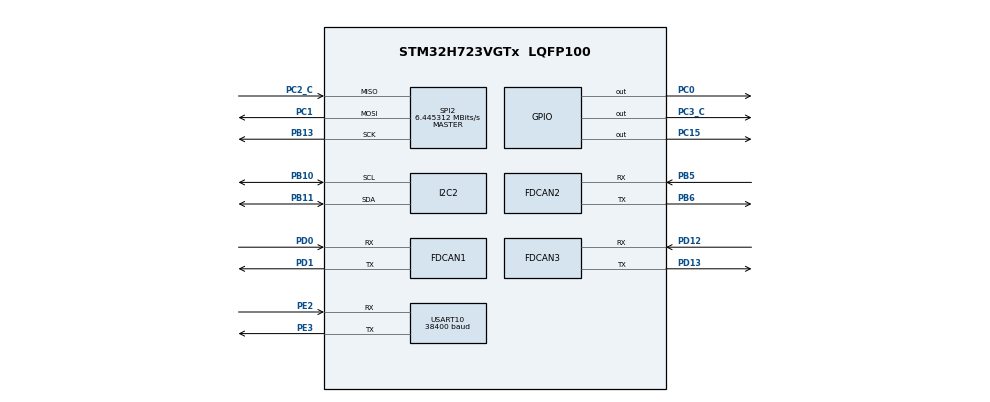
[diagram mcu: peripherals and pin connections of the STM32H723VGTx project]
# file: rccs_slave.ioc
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CORTEX_M7.AccessPermission_S-Cortex_Memory_Protection_Unit_Region1_Settings_S=MPU_REGION_FULL_ACCESS
CORTEX_M7.BaseAddress_S-Cortex_Memory_Protection_Unit_Region1_Settings_S=0x30000000
CORTEX_M7.DisableExec_S-Cortex_Memory_Protection_Unit_Region1_Settings_S=MPU_INSTRUCTION_ACCESS_DISABLE
CORTEX_M7.Enable_S-Cortex_Memory_Protection_Unit_Region1_Settings_S=MPU_REGION_ENABLE
CORTEX_M7.IsShareable_S-Cortex_Memory_Protection_Unit_Region1_Settings_S=MPU_ACCESS_SHAREABLE
CORTEX_M7.Size_S-Cortex_Memory_Protection_Unit_Region1_Settings_S=MPU_REGION_SIZE_32KB
CORTEX_M7.default_mode_Activation=1
Dma.I2C2_RX.2.Direction=DMA_PERIPH_TO_MEMORY
Dma.I2C2_RX.2.EventEnable=DISABLE
Dma.I2C2_RX.2.FIFOMode=DMA_FIFOMODE_DISABLE
Dma.I2C2_RX.2.Instance=DMA1_Stream2
Dma.I2C2_RX.2.MemDataAlignment=DMA_MDATAALIGN_BYTE
Dma.I2C2_RX.2.MemInc=DMA_MINC_ENABLE
Dma.I2C2_RX.2.Mode=DMA_NORMAL
Dma.I2C2_RX.2.PeriphDataAlignment=DMA_PDATAALIGN_BYTE
Dma.I2C2_RX.2.PeriphInc=DMA_PINC_DISABLE
Dma.I2C2_RX.2.Polarity=HAL_DMAMUX_REQ_GEN_RISING
Dma.I2C2_RX.2.Priority=DMA_PRIORITY_MEDIUM
Dma.I2C2_RX.2.RequestNumber=1
Dma.I2C2_RX.2.SignalID=NONE
Dma.I2C2_RX.2.SyncEnable=DISABLE
Dma.I2C2_RX.2.SyncPolarity=HAL_DMAMUX_SYNC_NO_EVENT
Dma.I2C2_RX.2.SyncRequestNumber=1
Dma.I2C2_RX.2.SyncSignalID=NONE
Dma.I2C2_TX.3.Direction=DMA_MEMORY_TO_PERIPH
Dma.I2C2_TX.3.EventEnable=DISABLE
Dma.I2C2_TX.3.FIFOMode=DMA_FIFOMODE_DISABLE
Dma.I2C2_TX.3.Instance=DMA1_Stream3
Dma.I2C2_TX.3.MemDataAlignment=DMA_MDATAALIGN_BYTE
Dma.I2C2_TX.3.MemInc=DMA_MINC_ENABLE
Dma.I2C2_TX.3.Mode=DMA_NORMAL
Dma.I2C2_TX.3.PeriphDataAlignment=DMA_PDATAALIGN_BYTE
Dma.I2C2_TX.3.PeriphInc=DMA_PINC_DISABLE
Dma.I2C2_TX.3.Polarity=HAL_DMAMUX_REQ_GEN_RISING
Dma.I2C2_TX.3.Priority=DMA_PRIORITY_MEDIUM
Dma.I2C2_TX.3.RequestNumber=1
Dma.I2C2_TX.3.SignalID=NONE
Dma.I2C2_TX.3.SyncEnable=DISABLE
Dma.I2C2_TX.3.SyncPolarity=HAL_DMAMUX_SYNC_NO_EVENT
Dma.I2C2_TX.3.SyncRequestNumber=1
Dma.I2C2_TX.3.SyncSignalID=NONE
Dma.Request0=SPI2_RX
Dma.Request1=SPI2_TX
Dma.Request2=I2C2_RX
Dma.Request3=I2C2_TX
Dma.Request4=USART10_RX
Dma.SPI2_RX.0.Direction=DMA_PERIPH_TO_MEMORY
Dma.SPI2_RX.0.EventEnable=DISABLE
Dma.SPI2_RX.0.FIFOMode=DMA_FIFOMODE_DISABLE
Dma.SPI2_RX.0.Instance=DMA1_Stream0
Dma.SPI2_RX.0.MemDataAlignment=DMA_MDATAALIGN_BYTE
Dma.SPI2_RX.0.MemInc=DMA_MINC_ENABLE
Dma.SPI2_RX.0.Mode=DMA_NORMAL
Dma.SPI2_RX.0.PeriphDataAlignment=DMA_PDATAALIGN_BYTE
Dma.SPI2_RX.0.PeriphInc=DMA_PINC_DISABLE
Dma.SPI2_RX.0.Polarity=HAL_DMAMUX_REQ_GEN_RISING
Dma.SPI2_RX.0.Priority=DMA_PRIORITY_LOW
Dma.SPI2_RX.0.RequestNumber=1
Dma.SPI2_RX.0.SignalID=NONE
Dma.SPI2_RX.0.SyncEnable=DISABLE
Dma.SPI2_RX.0.SyncPolarity=HAL_DMAMUX_SYNC_NO_EVENT
Dma.SPI2_RX.0.SyncRequestNumber=1
Dma.SPI2_RX.0.SyncSignalID=NONE
Dma.SPI2_TX.1.Direction=DMA_MEMORY_TO_PERIPH
Dma.SPI2_TX.1.EventEnable=DISABLE
Dma.SPI2_TX.1.FIFOMode=DMA_FIFOMODE_DISABLE
Dma.SPI2_TX.1.Instance=DMA1_Stream1
Dma.SPI2_TX.1.MemDataAlignment=DMA_MDATAALIGN_BYTE
Dma.SPI2_TX.1.MemInc=DMA_MINC_ENABLE
Dma.SPI2_TX.1.Mode=DMA_NORMAL
Dma.SPI2_TX.1.PeriphDataAlignment=DMA_PDATAALIGN_BYTE
Dma.SPI2_TX.1.PeriphInc=DMA_PINC_DISABLE
Dma.SPI2_TX.1.Polarity=HAL_DMAMUX_REQ_GEN_RISING
Dma.SPI2_TX.1.Priority=DMA_PRIORITY_LOW
Dma.SPI2_TX.1.RequestNumber=1
Dma.SPI2_TX.1.SignalID=NONE
Dma.SPI2_TX.1.SyncEnable=DISABLE
Dma.SPI2_TX.1.SyncPolarity=HAL_DMAMUX_SYNC_NO_EVENT
Dma.SPI2_TX.1.SyncRequestNumber=1
Dma.SPI2_TX.1.SyncSignalID=NONE
Dma.USART10_RX.4.Direction=DMA_PERIPH_TO_MEMORY
Dma.USART10_RX.4.EventEnable=DISABLE
Dma.USART10_RX.4.FIFOMode=DMA_FIFOMODE_DISABLE
Dma.USART10_RX.4.Instance=DMA1_Stream6
Dma.USART10_RX.4.MemDataAlignment=DMA_MDATAALIGN_BYTE
Dma.USART10_RX.4.MemInc=DMA_MINC_ENABLE
Dma.USART10_RX.4.Mode=DMA_CIRCULAR
Dma.USART10_RX.4.PeriphDataAlignment=DMA_PDATAALIGN_BYTE
Dma.USART10_RX.4.PeriphInc=DMA_PINC_DISABLE
Dma.USART10_RX.4.Polarity=HAL_DMAMUX_REQ_GEN_RISING
Dma.USART10_RX.4.Priority=DMA_PRIORITY_LOW
Dma.USART10_RX.4.RequestNumber=1
Dma.USART10_RX.4.SignalID=NONE
Dma.USART10_RX.4.SyncEnable=DISABLE
Dma.USART10_RX.4.SyncPolarity=HAL_DMAMUX_SYNC_NO_EVENT
Dma.USART10_RX.4.SyncRequestNumber=1
Dma.USART10_RX.4.SyncSignalID=NONE
FDCAN1.CalculateBaudRateNominal=1000000
FDCAN1.CalculateTimeBitNominal=1000
FDCAN1.CalculateTimeQuantumNominal=41.666666666666664
FDCAN1.NominalPrescaler=1
FDCAN1.NominalSyncJumpWidth=3
FDCAN1.NominalTimeSeg1=20
FDCAN1.NominalTimeSeg2=3
FDCAN1.RxFifo0ElmtsNbr=32
FDCAN1.StdFiltersNbr=8
FDCAN1.TxFifoQueueElmtsNbr=32
FDCAN2.CalculateBaudRateNominal=1000000
FDCAN2.CalculateTimeBitNominal=1000
FDCAN2.CalculateTimeQuantumNominal=41.666666666666664
FDCAN2.MessageRAMOffset=264
FDCAN2.NominalPrescaler=1
FDCAN2.NominalSyncJumpWidth=3
FDCAN2.NominalTimeSeg1=20
FDCAN2.NominalTimeSeg2=3
FDCAN2.RxFifo0ElmtsNbr=32
FDCAN2.TxFifoQueueElmtsNbr=32
FDCAN3.CalculateBaudRateNominal=1000000
FDCAN3.CalculateTimeBitNominal=1000
FDCAN3.CalculateTimeQuantumNominal=41.666666666666664
FDCAN3.MessageRAMOffset=528
FDCAN3.NominalPrescaler=1
FDCAN3.NominalSyncJumpWidth=3
FDCAN3.NominalTimeSeg1=20
FDCAN3.NominalTimeSeg2=3
FDCAN3.RxFifo0ElmtsNbr=32
FDCAN3.TxFifoQueueElmtsNbr=32
I2C2.Timing=0x60404E72
Mcu.Family=STM32H7
Mcu.Name=STM32H723VGTx
Mcu.Package=LQFP100
NVIC.DMA1_Stream0_IRQn=true\:0\:0\:false\:false\:true\:false\:true\:true
NVIC.DMA1_Stream1_IRQn=true\:1\:0\:true\:false\:true\:false\:true\:true
NVIC.DMA1_Stream2_IRQn=true\:0\:0\:false\:false\:true\:false\:true\:true
NVIC.DMA1_Stream3_IRQn=true\:0\:0\:false\:false\:true\:false\:true\:true
NVIC.DMA1_Stream6_IRQn=true\:1\:0\:true\:false\:true\:false\:true\:true
NVIC.FDCAN1_IT0_IRQn=true\:0\:0\:false\:false\:true\:true\:true\:true
NVIC.FDCAN2_IT0_IRQn=true\:0\:0\:false\:false\:true\:true\:true\:true
NVIC.FDCAN3_IT0_IRQn=true\:0\:0\:false\:false\:true\:true\:true\:true
NVIC.I2C2_ER_IRQn=true\:0\:0\:false\:false\:true\:true\:true\:true
NVIC.I2C2_EV_IRQn=true\:0\:0\:false\:false\:true\:true\:true\:true
NVIC.PriorityGroup=NVIC_PRIORITYGROUP_4
NVIC.SPI2_IRQn=true\:0\:0\:false\:false\:true\:false\:true\:true
NVIC.USART10_IRQn=true\:1\:0\:true\:false\:true\:true\:true\:true
PA10.Signal=USART1_RX
PA13(JTMS/SWDIO).Mode=Serial_Wire
PA13(JTMS/SWDIO).Signal=DEBUG_JTMS-SWDIO
PA14(JTCK/SWCLK).Mode=Serial_Wire
PA14(JTCK/SWCLK).Signal=DEBUG_JTCK-SWCLK
PA9.Signal=USART1_TX
PB10.Mode=I2C
PB10.Signal=I2C2_SCL
PB11.Mode=I2C
PB11.Signal=I2C2_SDA
PB13.Mode=Full_Duplex_Master
PB13.Signal=SPI2_SCK
PB5.Mode=FDCAN_Activate
PB5.Signal=FDCAN2_RX
PB6.Mode=FDCAN_Activate
PB6.Signal=FDCAN2_TX
PC0.GPIO_ModeDefaultOutputPP=GPIO_MODE_OUTPUT_PP
PC0.GPIO_PuPd=GPIO_PULLUP
PC0.GPIO_Speed=GPIO_SPEED_FREQ_VERY_HIGH
PC0.PinState=GPIO_PIN_SET
PC0.Signal=GPIO_Output
PC1.Mode=Full_Duplex_Master
PC1.Signal=SPI2_MOSI
PC15-OSC32_OUT.GPIO_PuPd=GPIO_PULLUP
PC15-OSC32_OUT.PinState=GPIO_PIN_SET
PC15-OSC32_OUT.Signal=GPIO_Output
PC2_C.Mode=Full_Duplex_Master
PC2_C.Signal=SPI2_MISO
PC3_C.GPIO_ModeDefaultOutputPP=GPIO_MODE_OUTPUT_PP
PC3_C.GPIO_PuPd=GPIO_PULLUP
PC3_C.GPIO_Speed=GPIO_SPEED_FREQ_VERY_HIGH
PC3_C.PinState=GPIO_PIN_SET
PC3_C.Signal=GPIO_Output
PD0.Mode=FDCAN_Activate
PD0.Signal=FDCAN1_RX
PD1.Mode=FDCAN_Activate
PD1.Signal=FDCAN1_TX
PD12.Mode=FDCAN_Activate
PD12.Signal=FDCAN3_RX
PD13.Mode=FDCAN_Activate
PD13.Signal=FDCAN3_TX
PE2.GPIO_PuPd=GPIO_PULLUP
PE2.Mode=Asynchronous
PE2.Signal=USART10_RX
PE3.Mode=Asynchronous
PE3.Signal=USART10_TX
PH0-OSC_IN.Mode=HSE-External-Oscillator
PH0-OSC_IN.Signal=RCC_OSC_IN
PH1-OSC_OUT.Mode=HSE-External-Oscillator
PH1-OSC_OUT.Signal=RCC_OSC_OUT
ProjectManager.HeapSize=0x200
ProjectManager.StackSize=0x400
ProjectManager.TargetToolchain=Makefile
RCC.ADCFreq_Value=48375000
RCC.APB1Freq_Value=137500000
RCC.APB2Freq_Value=137500000
RCC.APB3Freq_Value=137500000
RCC.APB4Freq_Value=137500000
RCC.CortexFreq_Value=275000000
RCC.D1PPRE=RCC_APB3_DIV2
RCC.D2PPRE1=RCC_APB1_DIV2
RCC.D2PPRE2=RCC_APB2_DIV2
RCC.D3PPRE=RCC_APB4_DIV2
RCC.DIVM1=2
RCC.DIVN1=68
RCC.DIVP1=3
RCC.DIVQ1=4
RCC.FDCANCLockSelection=RCC_FDCANCLKSOURCE_HSE
RCC.HCLKFreq_Value=275000000
RCC.HSE_VALUE=24000000
RCC.PLLFRACN=6144
RCC.PLLSourceVirtual=RCC_PLLSOURCE_HSE
RCC.SYSCLKFreq_VALUE=275000000
RCC.SYSCLKSource=RCC_SYSCLKSOURCE_PLLCLK
RCC.USBFreq_Value=206250000
SPI2.BaudRatePrescaler=SPI_BAUDRATEPRESCALER_32
SPI2.CalculateBaudRate=6.445312 MBits/s
SPI2.DataSize=SPI_DATASIZE_8BIT
SPI2.Direction=SPI_DIRECTION_2LINES
SPI2.Mode=SPI_MODE_MASTER
SPI2.NSSPMode=SPI_NSS_PULSE_DISABLE
SPI2.VirtualType=VM_MASTER
USART10.BaudRate=38400
USART10.DMADisableonRxErrorParam=ADVFEATURE_DMA_DISABLEONRXERROR
USART10.Mode=MODE_RX
USART10.VirtualMode=VM_ASYNC
VP_MEMORYMAP_VS_MEMORYMAP.Mode=CurAppReg
board=custom

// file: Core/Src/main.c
/* USER CODE BEGIN Header */
/**
  ******************************************************************************
  * @file           : main.c
  * @brief          : Main program body
  ******************************************************************************
  * @attention
  *
  * Copyright (c) 2026 STMicroelectronics.
  * All rights reserved.
  *
  * This software is licensed under terms that can be found in the LICENSE file
  * in the root directory of this software component.
  * If no LICENSE file comes with this software, it is provided AS-IS.
  *
  ******************************************************************************
  */
/* USER CODE END Header */
#include "main.h"
#include "dma.h"
#include "fdcan.h"
#include "i2c.h"
#include "spi.h"
#include "usart.h"
#include "gpio.h"

/* USER CODE BEGIN Includes */
#include "app/app_entry.h"
/* USER CODE END Includes */

void SystemClock_Config(void);
static void MPU_Config(void);

int main(void)
{

  /* MPU Configuration--------------------------------------------------------*/
  MPU_Config();

  /* MCU Configuration--------------------------------------------------------*/

  /* Reset of all peripherals, Initializes the Flash interface and the Systick. */
  HAL_Init();

  /* Configure the system clock */
  SystemClock_Config();

  /* Initialize all configured peripherals */
  MX_GPIO_Init();
  MX_DMA_Init();
  MX_SPI2_Init();
  MX_FDCAN1_Init();
  MX_FDCAN2_Init();
  MX_FDCAN3_Init();
  MX_I2C2_Init();
  MX_USART10_UART_Init();
  /* USER CODE BEGIN 2 */
  if(!App_Init()){
      Error_Handler();
  }
  /* USER CODE END 2 */

  /* Infinite loop */
  while (1)
  {

    /* USER CODE BEGIN 3 */
    App_Process();
  }
  /* USER CODE END 3 */
}

void SystemClock_Config(void)
{
  RCC_OscInitTypeDef RCC_OscInitStruct = {0};
  RCC_ClkInitTypeDef RCC_ClkInitStruct = {0};

  /** Supply configuration update enable
  */
  HAL_PWREx_ConfigSupply(PWR_LDO_SUPPLY);

  /** Configure the main internal regulator output voltage
  */
  __HAL_PWR_VOLTAGESCALING_CONFIG(PWR_REGULATOR_VOLTAGE_SCALE0);

  while(!__HAL_PWR_GET_FLAG(PWR_FLAG_VOSRDY)) {}

  /** Initializes the RCC Oscillators according to the specified parameters
  * in the RCC_OscInitTypeDef structure.
  */
  RCC_OscInitStruct.OscillatorType = RCC_OSCILLATORTYPE_HSE;
  RCC_OscInitStruct.HSEState = RCC_HSE_ON;
  RCC_OscInitStruct.PLL.PLLState = RCC_PLL_ON;
  RCC_OscInitStruct.PLL.PLLSource = RCC_PLLSOURCE_HSE;
  RCC_OscInitStruct.PLL.PLLM = 2;
  RCC_OscInitStruct.PLL.PLLN = 68;
  RCC_OscInitStruct.PLL.PLLP = 3;
  RCC_OscInitStruct.PLL.PLLQ = 4;
  RCC_OscInitStruct.PLL.PLLR = 2;
  RCC_OscInitStruct.PLL.PLLRGE = RCC_PLL1VCIRANGE_3;
  RCC_OscInitStruct.PLL.PLLVCOSEL = RCC_PLL1VCOWIDE;
  RCC_OscInitStruct.PLL.PLLFRACN = 6144;
  if (HAL_RCC_OscConfig(&RCC_OscInitStruct) != HAL_OK)
  {
    Error_Handler();
  }

  /** Initializes the CPU, AHB and APB buses clocks
  */
  RCC_ClkInitStruct.ClockType = RCC_CLOCKTYPE_HCLK|RCC_CLOCKTYPE_SYSCLK
                              |RCC_CLOCKTYPE_PCLK1|RCC_CLOCKTYPE_PCLK2
                              |RCC_CLOCKTYPE_D3PCLK1|RCC_CLOCKTYPE_D1PCLK1;
  RCC_ClkInitStruct.SYSCLKSource = RCC_SYSCLKSOURCE_PLLCLK;
  RCC_ClkInitStruct.SYSCLKDivider = RCC_SYSCLK_DIV1;
  RCC_ClkInitStruct.AHBCLKDivider = RCC_HCLK_DIV1;
  RCC_ClkInitStruct.APB3CLKDivider = RCC_APB3_DIV2;
  RCC_ClkInitStruct.APB1CLKDivider = RCC_APB1_DIV2;
  RCC_ClkInitStruct.APB2CLKDivider = RCC_APB2_DIV2;
  RCC_ClkInitStruct.APB4CLKDivider = RCC_APB4_DIV2;

  if (HAL_RCC_ClockConfig(&RCC_ClkInitStruct, FLASH_LATENCY_3) != HAL_OK)
  {
    Error_Handler();
  }
}

 /* MPU Configuration */

void MPU_Config(void)
{
  MPU_Region_InitTypeDef MPU_InitStruct = {0};

  /* Disables the MPU */
  HAL_MPU_Disable();

  /** Initializes and configures the Region and the memory to be protected
  */
  MPU_InitStruct.Enable = MPU_REGION_ENABLE;
  MPU_InitStruct.Number = MPU_REGION_NUMBER0;
  MPU_InitStruct.BaseAddress = 0x0;
  MPU_InitStruct.Size = MPU_REGION_SIZE_4GB;
  MPU_InitStruct.SubRegionDisable = 0x87;
  MPU_InitStruct.TypeExtField = MPU_TEX_LEVEL0;
  MPU_InitStruct.AccessPermission = MPU_REGION_NO_ACCESS;
  MPU_InitStruct.DisableExec = MPU_INSTRUCTION_ACCESS_DISABLE;
  MPU_InitStruct.IsShareable = MPU_ACCESS_SHAREABLE;
  MPU_InitStruct.IsCacheable = MPU_ACCESS_NOT_CACHEABLE;
  MPU_InitStruct.IsBufferable = MPU_ACCESS_NOT_BUFFERABLE;

  HAL_MPU_ConfigRegion(&MPU_InitStruct);

  /** Initializes and configures the Region and the memory to be protected
  */
  MPU_InitStruct.Number = MPU_REGION_NUMBER1;
  MPU_InitStruct.BaseAddress = 0x30000000;
  MPU_InitStruct.Size = MPU_REGION_SIZE_32KB;
  MPU_InitStruct.SubRegionDisable = 0x0;
  MPU_InitStruct.AccessPermission = MPU_REGION_FULL_ACCESS;

  HAL_MPU_ConfigRegion(&MPU_InitStruct);
  /* Enables the MPU */
  HAL_MPU_Enable(MPU_PRIVILEGED_DEFAULT);

}

void Error_Handler(void)
{
  __disable_irq();
  while (1)
  {
  }
}
